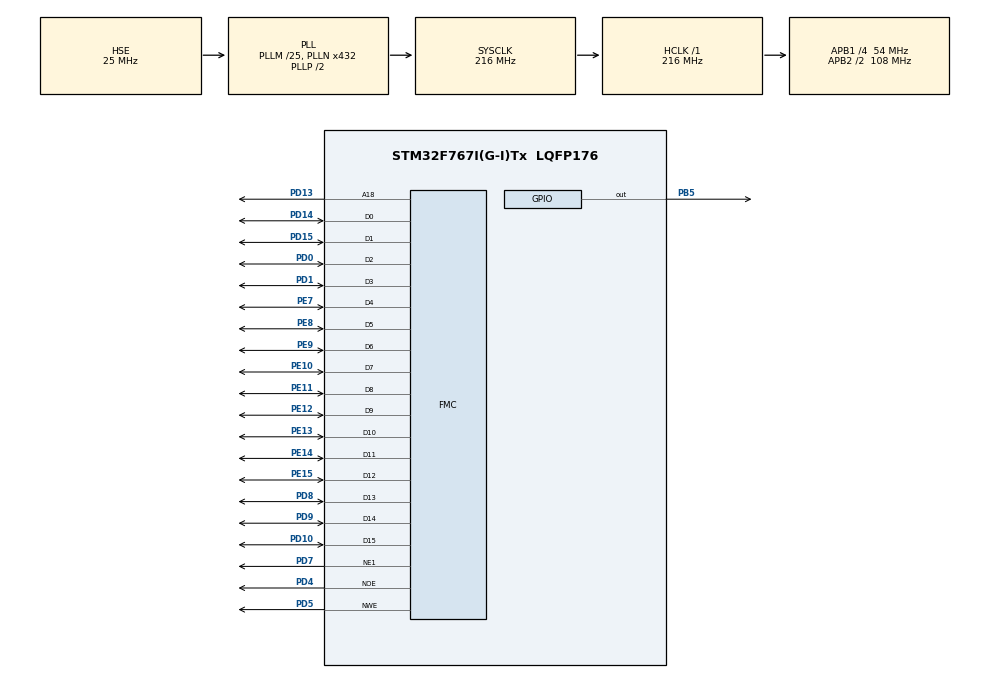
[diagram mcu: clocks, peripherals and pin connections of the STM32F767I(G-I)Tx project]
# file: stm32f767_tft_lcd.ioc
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Mcu.Family=STM32F7
PD7.Mode=NorPsramChipSelect1_1
SH.FMC_D7_DA7.0=FMC_D7,16b-d1
RCC.CortexFreq_Value=216000000
SH.FMC_D14_DA14.0=FMC_D14,16b-d1
SH.FMC_D6_DA6.0=FMC_D6,16b-d1
PC14/OSC32_IN.Mode=LSE-External-Oscillator
SH.FMC_D5_DA5.0=FMC_D5,16b-d1
FMC.WriteOperation1=FMC_WRITE_OPERATION_ENABLE
SH.FMC_NWE.0=FMC_NWE,Lcd1
RCC.SYSCLKSource=RCC_SYSCLKSOURCE_PLLCLK
ProjectManager.StackSize=0x400
SH.FMC_D9_DA9.0=FMC_D9,16b-d1
PD13.Signal=FMC_A18
CORTEX_M7.Enable-Cortex_Memory_Protection_Unit_Region0_Settings=MPU_REGION_ENABLE
SH.FMC_D11_DA11.0=FMC_D11,16b-d1
PH0/OSC_IN.Mode=HSE-External-Oscillator
RCC.HCLKFreq_Value=216000000
PD4.Signal=FMC_NOE
RCC.APB2TimFreq_Value=216000000
PH1/OSC_OUT.Signal=RCC_OSC_OUT
PD0.Signal=FMC_D2_DA2
PD8.Signal=FMC_D13_DA13
RCC.AHBFreq_Value=216000000
SH.FMC_A18.0=FMC_A18,A18_1
RCC.HSE_VALUE=25000000
SH.FMC_D8_DA8.0=FMC_D8,16b-d1
SH.FMC_D2_DA2.0=FMC_D2,16b-d1
FMC.BusTurnAroundDuration1=1
PE13.Signal=FMC_D10_DA10
FMC.DataSetupTime1=4
PE9.Signal=FMC_D6_DA6
PA14.Mode=Serial_Wire
SH.FMC_D1_DA1.0=FMC_D1,16b-d1
PH1/OSC_OUT.Mode=HSE-External-Oscillator
PE10.Signal=FMC_D7_DA7
Mcu.Package=LQFP176
SH.FMC_D0_DA0.0=FMC_D0,16b-d1
PC14/OSC32_IN.Signal=RCC_OSC32_IN
FMC.ExtendedDataSetupTime1=4
SH.FMC_D4_DA4.0=FMC_D4,16b-d1
RCC.APB2CLKDivider=RCC_HCLK_DIV2
FMC.ExtendedAddressSetupTime1=0
RCC.APB1TimFreq_Value=108000000
PE7.Signal=FMC_D4_DA4
PD15.Signal=FMC_D1_DA1
SH.FMC_D3_DA3.0=FMC_D3,16b-d1
CORTEX_M7.IsBufferable-Cortex_Memory_Protection_Unit_Region0_Settings=MPU_ACCESS_BUFFERABLE
RCC.PLLSourceVirtual=RCC_PLLSOURCE_HSE
CORTEX_M7.CPU_ICache=Enabled
FMC.ExtendedMode1=FMC_EXTENDED_MODE_ENABLE
FMC.WriteFifo3=FMC_WRITE_FIFO_DISABLE
FMC.WriteFifo4=FMC_WRITE_FIFO_DISABLE
FMC.WriteFifo1=FMC_WRITE_FIFO_DISABLE
SH.FMC_D10_DA10.0=FMC_D10,16b-d1
FMC.WriteFifo2=FMC_WRITE_FIFO_DISABLE
PD7.Signal=FMC_NE1
PD1.Signal=FMC_D3_DA3
PD5.Signal=FMC_NWE
PD9.Signal=FMC_D14_DA14
RCC.APB1CLKDivider=RCC_HCLK_DIV4
SH.FMC_NOE.0=FMC_NOE,Lcd1
PD10.Signal=FMC_D15_DA15
PA13.Signal=SYS_JTMS-SWDIO
FMC.AddressSetupTime1=3
CORTEX_M7.MPU_Control=MPU_HFNMI_PRIVDEF
ProjectManager.TargetToolchain=Makefile
SH.FMC_D15_DA15.0=FMC_D15,16b-d1
SH.FMC_D13_DA13.0=FMC_D13,16b-d1
FMC.ExtendedBusTurnAroundDuration1=1
CORTEX_M7.BaseAddress-Cortex_Memory_Protection_Unit_Region0_Settings=0x60000000
RCC.USBFreq_Value=216000000
PE11.Signal=FMC_D8_DA8
board=custom
RCC.VCOOutputFreq_Value=432000000
PH0/OSC_IN.Signal=RCC_OSC_IN
RCC.APB2Freq_Value=108000000
PE14.Signal=FMC_D11_DA11
PE15.Signal=FMC_D12_DA12
PE8.Signal=FMC_D5_DA5
CORTEX_M7.AccessPermission-Cortex_Memory_Protection_Unit_Region0_Settings=MPU_REGION_FULL_ACCESS
SH.FMC_D12_DA12.0=FMC_D12,16b-d1
PA13.Mode=Serial_Wire
Mcu.Name=STM32F767I(G-I)Tx
CORTEX_M7.Size-Cortex_Memory_Protection_Unit_Region0_Settings=MPU_REGION_SIZE_256MB
PE12.Signal=FMC_D9_DA9
PD14.Signal=FMC_D0_DA0
RCC.SYSCLKFreq_VALUE=216000000
PB5.Signal=GPIO_Output
PC15/OSC32_OUT.Mode=LSE-External-Oscillator
PA14.Signal=SYS_JTCK-SWCLK
ProjectManager.HeapSize=0x200
RCC.HSI_VALUE=16000000
NVIC.PriorityGroup=NVIC_PRIORITYGROUP_4
RCC.PLLM=25
RCC.PLLN=432
PC15/OSC32_OUT.Signal=RCC_OSC32_OUT
CORTEX_M7.CPU_DCache=Enabled
RCC.APB1Freq_Value=54000000

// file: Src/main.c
/* USER CODE BEGIN Header */
/**
  ******************************************************************************
  * @file           : main.c
  * @brief          : Main program body
  ******************************************************************************
  * @attention
  *
  * <h2><center>&copy; Copyright (c) 2020 STMicroelectronics.
  * All rights reserved.</center></h2>
  *
  * This software component is licensed by ST under BSD 3-Clause license,
  * the "License"; You may not use this file except in compliance with the
  * License. You may obtain a copy of the License at:
  *                        opensource.org/licenses/BSD-3-Clause
  *
  ******************************************************************************
  */
/* USER CODE END Header */
#include "main.h"
#include "gpio.h"
#include "fmc.h"

void SystemClock_Config(void);
static void MPU_Config(void);

int main(void)
{

  /* MPU Configuration--------------------------------------------------------*/
  MPU_Config();

  /* Enable I-Cache---------------------------------------------------------*/
  SCB_EnableICache();

  /* Enable D-Cache---------------------------------------------------------*/
  SCB_EnableDCache();

  /* MCU Configuration--------------------------------------------------------*/

  /* Reset of all peripherals, Initializes the Flash interface and the Systick. */
  HAL_Init();

  /* Configure the system clock */
  SystemClock_Config();

  /* Initialize all configured peripherals */
  MX_GPIO_Init();
  MX_FMC_Init();

  /* Infinite loop */
  /* USER CODE BEGIN WHILE */
  void lcd_init();
  lcd_init();

  while (1)
  {
    /* USER CODE END WHILE */

  }
}

void SystemClock_Config(void)
{
  RCC_OscInitTypeDef RCC_OscInitStruct = {0};
  RCC_ClkInitTypeDef RCC_ClkInitStruct = {0};

  /** Configure LSE Drive Capability
  */
  HAL_PWR_EnableBkUpAccess();
  /** Configure the main internal regulator output voltage
  */
  __HAL_RCC_PWR_CLK_ENABLE();
  __HAL_PWR_VOLTAGESCALING_CONFIG(PWR_REGULATOR_VOLTAGE_SCALE1);
  /** Initializes the RCC Oscillators according to the specified parameters
  * in the RCC_OscInitTypeDef structure.
  */
  RCC_OscInitStruct.OscillatorType = RCC_OSCILLATORTYPE_HSE;
  RCC_OscInitStruct.HSEState = RCC_HSE_ON;
  RCC_OscInitStruct.PLL.PLLState = RCC_PLL_ON;
  RCC_OscInitStruct.PLL.PLLSource = RCC_PLLSOURCE_HSE;
  RCC_OscInitStruct.PLL.PLLM = 25;
  RCC_OscInitStruct.PLL.PLLN = 432;
  RCC_OscInitStruct.PLL.PLLP = RCC_PLLP_DIV2;
  RCC_OscInitStruct.PLL.PLLQ = 2;
  if (HAL_RCC_OscConfig(&RCC_OscInitStruct) != HAL_OK)
  {
    Error_Handler();
  }
  /** Activate the Over-Drive mode
  */
  if (HAL_PWREx_EnableOverDrive() != HAL_OK)
  {
    Error_Handler();
  }
  /** Initializes the CPU, AHB and APB buses clocks
  */
  RCC_ClkInitStruct.ClockType = RCC_CLOCKTYPE_HCLK|RCC_CLOCKTYPE_SYSCLK
                              |RCC_CLOCKTYPE_PCLK1|RCC_CLOCKTYPE_PCLK2;
  RCC_ClkInitStruct.SYSCLKSource = RCC_SYSCLKSOURCE_PLLCLK;
  RCC_ClkInitStruct.AHBCLKDivider = RCC_SYSCLK_DIV1;
  RCC_ClkInitStruct.APB1CLKDivider = RCC_HCLK_DIV4;
  RCC_ClkInitStruct.APB2CLKDivider = RCC_HCLK_DIV2;

  if (HAL_RCC_ClockConfig(&RCC_ClkInitStruct, FLASH_LATENCY_7) != HAL_OK)
  {
    Error_Handler();
  }
}

/* MPU Configuration */

void MPU_Config(void)
{
  MPU_Region_InitTypeDef MPU_InitStruct = {0};

  /* Disables the MPU */
  HAL_MPU_Disable();
  /** Initializes and configures the Region and the memory to be protected
  */
  MPU_InitStruct.Enable = MPU_REGION_ENABLE;
  MPU_InitStruct.Number = MPU_REGION_NUMBER0;
  MPU_InitStruct.BaseAddress = 0x60000000;
  MPU_InitStruct.Size = MPU_REGION_SIZE_256MB;
  MPU_InitStruct.SubRegionDisable = 0x0;
  MPU_InitStruct.TypeExtField = MPU_TEX_LEVEL0;
  MPU_InitStruct.AccessPermission = MPU_REGION_FULL_ACCESS;
  MPU_InitStruct.DisableExec = MPU_INSTRUCTION_ACCESS_ENABLE;
  MPU_InitStruct.IsShareable = MPU_ACCESS_NOT_SHAREABLE;
  MPU_InitStruct.IsCacheable = MPU_ACCESS_NOT_CACHEABLE;
  MPU_InitStruct.IsBufferable = MPU_ACCESS_BUFFERABLE;

  HAL_MPU_ConfigRegion(&MPU_InitStruct);
  /* Enables the MPU */
  HAL_MPU_Enable(MPU_HFNMI_PRIVDEF);

}

void Error_Handler(void)
{
  __disable_irq();
  while (1)
  {
  }
}

/************************ (C) COPYRIGHT STMicroelectronics *****END OF FILE****/
